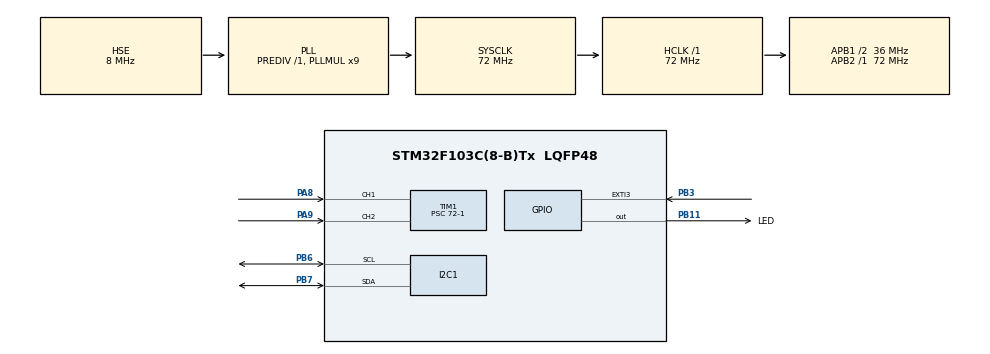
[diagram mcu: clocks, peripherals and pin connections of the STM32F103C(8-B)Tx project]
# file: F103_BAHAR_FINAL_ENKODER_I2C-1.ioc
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I2C1.I2C_Mode=I2C_Fast
Mcu.Family=STM32F1
Mcu.Name=STM32F103C(8-B)Tx
Mcu.Package=LQFP48
NVIC.EXTI3_IRQn=true\:0\:0\:false\:false\:true\:true\:true
NVIC.I2C1_ER_IRQn=true\:0\:0\:false\:false\:true\:true\:true
NVIC.I2C1_EV_IRQn=true\:0\:0\:false\:false\:true\:true\:true
NVIC.PriorityGroup=NVIC_PRIORITYGROUP_4
NVIC.TIM1_BRK_IRQn=true\:0\:0\:false\:false\:true\:true\:true
NVIC.TIM1_CC_IRQn=true\:0\:0\:false\:false\:true\:true\:true
NVIC.TIM1_TRG_COM_IRQn=true\:0\:0\:false\:false\:true\:true\:true
NVIC.TIM1_UP_IRQn=true\:0\:0\:false\:false\:true\:true\:true
PA13.Mode=Serial_Wire
PA13.Signal=SYS_JTMS-SWDIO
PA14.Mode=Serial_Wire
PA14.Signal=SYS_JTCK-SWCLK
PA8.Signal=S_TIM1_CH1
PA9.Signal=S_TIM1_CH2
PB11.GPIO_Label=LED
PB11.Signal=GPIO_Output
PB3.GPIO_ModeDefaultEXTI=GPIO_MODE_IT_RISING_FALLING
PB3.Signal=GPXTI3
PB6.Mode=I2C
PB6.Signal=I2C1_SCL
PB7.Mode=I2C
PB7.Signal=I2C1_SDA
PD0-OSC_IN.Mode=HSE-External-Oscillator
PD0-OSC_IN.Signal=RCC_OSC_IN
PD1-OSC_OUT.Mode=HSE-External-Oscillator
PD1-OSC_OUT.Signal=RCC_OSC_OUT
ProjectManager.HeapSize=0x200
ProjectManager.StackSize=0x400
ProjectManager.TargetToolchain=SW4STM32
RCC.AHBFreq_Value=72000000
RCC.APB1CLKDivider=RCC_HCLK_DIV2
RCC.APB1Freq_Value=36000000
RCC.APB1TimFreq_Value=72000000
RCC.APB2Freq_Value=72000000
RCC.APB2TimFreq_Value=72000000
RCC.HCLKFreq_Value=72000000
RCC.PLLMUL=RCC_PLL_MUL9
RCC.PLLSourceVirtual=RCC_PLLSOURCE_HSE
RCC.SYSCLKFreq_VALUE=72000000
RCC.SYSCLKSource=RCC_SYSCLKSOURCE_PLLCLK
RCC.USBFreq_Value=72000000
SH.S_TIM1_CH1.0=TIM1_CH1,Encoder_Interface
SH.S_TIM1_CH2.0=TIM1_CH2,Encoder_Interface
TIM1.EncoderMode=TIM_ENCODERMODE_TI12
TIM1.IC2Polarity=TIM_ICPOLARITY_FALLING
TIM1.Period=4096-1
TIM1.Prescaler=72-1
board=custom

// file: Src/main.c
/* USER CODE BEGIN Header */
/**
  ******************************************************************************
  * @file           : main.c
  * @brief          : Main program body
  ******************************************************************************
  * @attention
  *
  * <h2><center>&copy; Copyright (c) 2019 STMicroelectronics.
  * All rights reserved.</center></h2>
  *
  * This software component is licensed by ST under BSD 3-Clause license,
  * the "License"; You may not use this file except in compliance with the
  * License. You may obtain a copy of the License at:
  *                        opensource.org/licenses/BSD-3-Clause
  *
  ******************************************************************************
  */
/* USER CODE END Header */

#include "main.h"

I2C_HandleTypeDef hi2c1;

TIM_HandleTypeDef htim1;

void SystemClock_Config(void);
static void MX_GPIO_Init(void);
static void MX_TIM1_Init(void);
static void MX_I2C1_Init(void);

/* USER CODE BEGIN 0 */
uint8_t aRxBuffer;
uint8_t aTxBuffer[5];

uint8_t sistem_durumu=0;
uint8_t enkoder_durumu=0;
int encoder_value = 0;
char strBuffer[5];

/* USER CODE END 0 */

int main(void)
{

  /* MCU Configuration--------------------------------------------------------*/

  /* Reset of all peripherals, Initializes the Flash interface and the Systick. */
  HAL_Init();

  /* Configure the system clock */
  SystemClock_Config();

  /* Initialize all configured peripherals */
  MX_GPIO_Init();
  MX_TIM1_Init();
  MX_I2C1_Init();

  /* Infinite loop */
  /* USER CODE BEGIN WHILE */
  while (1)
  {
	  if(sistem_durumu==1 && enkoder_durumu==1)
	  {
		  encoder_value = __HAL_TIM_GET_COUNTER(&htim1);
	  }
	  else if (sistem_durumu==1 && enkoder_durumu==0){
		  sprintf(strBuffer, "%d\n", encoder_value);
		  while(HAL_I2C_Slave_Transmit(&hi2c1,  (uint8_t*)strBuffer, 5, 1000) != HAL_OK){
		  if (HAL_I2C_GetError(&hi2c1) != HAL_I2C_ERROR_AF)
		  {
			Error_Handler();
		  }
		  encoder_value=0;
	  }
 }

void HAL_I2C_SlaveRxCpltCallback(I2C_HandleTypeDef *hi2c)
{
	if(HAL_I2C_Slave_Receive(&hi2c1, (uint8_t *)aRxBuffer, 1, 1000)!= HAL_OK){
	    Error_Handler();
	  }
	  while (HAL_I2C_GetState(&hi2c1) != HAL_I2C_STATE_READY) {}
	 if(aRxBuffer==(uint8_t)"B"){
		 sistem_durumu=1;
		 HAL_GPIO_WritePin(GPIOB, GPIO_PIN_11, GPIO_PIN_SET);
	 }
	 if(aRxBuffer==(uint8_t)"D"){
		 sistem_durumu=0;
		 HAL_GPIO_WritePin(GPIOB, GPIO_PIN_11, GPIO_PIN_RESET);
	 }
}

void HAL_GPIO_EXTI_Callback(uint16_t GPIO_Pin)
{
  if(GPIO_Pin == GPIO_PIN_3)
  {
	  if(HAL_GPIO_ReadPin(GPIOB, GPIO_PIN_3)==1){
		  HAL_TIM_Encoder_Start(&htim1, TIM_CHANNEL_ALL);
		  enkoder_durumu = 1;
	  }
	  else{
		  HAL_TIM_Encoder_Stop(&htim1, TIM_CHANNEL_ALL);
		  enkoder_durumu = 0;
	  }
  }
}
void SystemClock_Config(void)
{
  RCC_OscInitTypeDef RCC_OscInitStruct = {0};
  RCC_ClkInitTypeDef RCC_ClkInitStruct = {0};

  /** Initializes the CPU, AHB and APB busses clocks
  */
  RCC_OscInitStruct.OscillatorType = RCC_OSCILLATORTYPE_HSE;
  RCC_OscInitStruct.HSEState = RCC_HSE_ON;
  RCC_OscInitStruct.HSEPredivValue = RCC_HSE_PREDIV_DIV1;
  RCC_OscInitStruct.HSIState = RCC_HSI_ON;
  RCC_OscInitStruct.PLL.PLLState = RCC_PLL_ON;
  RCC_OscInitStruct.PLL.PLLSource = RCC_PLLSOURCE_HSE;
  RCC_OscInitStruct.PLL.PLLMUL = RCC_PLL_MUL9;
  if (HAL_RCC_OscConfig(&RCC_OscInitStruct) != HAL_OK)
  {
    Error_Handler();
  }
  /** Initializes the CPU, AHB and APB busses clocks
  */
  RCC_ClkInitStruct.ClockType = RCC_CLOCKTYPE_HCLK|RCC_CLOCKTYPE_SYSCLK
                              |RCC_CLOCKTYPE_PCLK1|RCC_CLOCKTYPE_PCLK2;
  RCC_ClkInitStruct.SYSCLKSource = RCC_SYSCLKSOURCE_PLLCLK;
  RCC_ClkInitStruct.AHBCLKDivider = RCC_SYSCLK_DIV1;
  RCC_ClkInitStruct.APB1CLKDivider = RCC_HCLK_DIV2;
  RCC_ClkInitStruct.APB2CLKDivider = RCC_HCLK_DIV1;

  if (HAL_RCC_ClockConfig(&RCC_ClkInitStruct, FLASH_LATENCY_2) != HAL_OK)
  {
    Error_Handler();
  }
}

static void MX_I2C1_Init(void)
{

  hi2c1.Instance = I2C1;
  hi2c1.Init.ClockSpeed = 400000;
  hi2c1.Init.DutyCycle = I2C_DUTYCYCLE_2;
  hi2c1.Init.OwnAddress1 = 0;
  hi2c1.Init.AddressingMode = I2C_ADDRESSINGMODE_7BIT;
  hi2c1.Init.DualAddressMode = I2C_DUALADDRESS_DISABLE;
  hi2c1.Init.OwnAddress2 = 0;
  hi2c1.Init.GeneralCallMode = I2C_GENERALCALL_DISABLE;
  hi2c1.Init.NoStretchMode = I2C_NOSTRETCH_DISABLE;
  if (HAL_I2C_Init(&hi2c1) != HAL_OK)
  {
    Error_Handler();
  }

}

static void MX_TIM1_Init(void)
{

  TIM_Encoder_InitTypeDef sConfig = {0};
  TIM_MasterConfigTypeDef sMasterConfig = {0};

  htim1.Instance = TIM1;
  htim1.Init.Prescaler = 72-1;
  htim1.Init.CounterMode = TIM_COUNTERMODE_UP;
  htim1.Init.Period = 4096-1;
  htim1.Init.ClockDivision = TIM_CLOCKDIVISION_DIV1;
  htim1.Init.RepetitionCounter = 0;
  htim1.Init.AutoReloadPreload = TIM_AUTORELOAD_PRELOAD_DISABLE;
  sConfig.EncoderMode = TIM_ENCODERMODE_TI12;
  sConfig.IC1Polarity = TIM_ICPOLARITY_RISING;
  sConfig.IC1Selection = TIM_ICSELECTION_DIRECTTI;
  sConfig.IC1Prescaler = TIM_ICPSC_DIV1;
  sConfig.IC1Filter = 0;
  sConfig.IC2Polarity = TIM_ICPOLARITY_FALLING;
  sConfig.IC2Selection = TIM_ICSELECTION_DIRECTTI;
  sConfig.IC2Prescaler = TIM_ICPSC_DIV1;
  sConfig.IC2Filter = 0;
  if (HAL_TIM_Encoder_Init(&htim1, &sConfig) != HAL_OK)
  {
    Error_Handler();
  }
  sMasterConfig.MasterOutputTrigger = TIM_TRGO_RESET;
  sMasterConfig.MasterSlaveMode = TIM_MASTERSLAVEMODE_DISABLE;
  if (HAL_TIMEx_MasterConfigSynchronization(&htim1, &sMasterConfig) != HAL_OK)
  {
    Error_Handler();
  }

}

static void MX_GPIO_Init(void)
{
  GPIO_InitTypeDef GPIO_InitStruct = {0};

  /* GPIO Ports Clock Enable */
  __HAL_RCC_GPIOD_CLK_ENABLE();
  __HAL_RCC_GPIOB_CLK_ENABLE();
  __HAL_RCC_GPIOA_CLK_ENABLE();

  /*Configure GPIO pin Output Level */
  HAL_GPIO_WritePin(LED_GPIO_Port, LED_Pin, GPIO_PIN_RESET);

  /*Configure GPIO pin : LED_Pin */
  GPIO_InitStruct.Pin = LED_Pin;
  GPIO_InitStruct.Mode = GPIO_MODE_OUTPUT_PP;
  GPIO_InitStruct.Pull = GPIO_NOPULL;
  GPIO_InitStruct.Speed = GPIO_SPEED_FREQ_LOW;
  HAL_GPIO_Init(LED_GPIO_Port, &GPIO_InitStruct);

  /*Configure GPIO pin : PB3 */
  GPIO_InitStruct.Pin = GPIO_PIN_3;
  GPIO_InitStruct.Mode = GPIO_MODE_IT_RISING_FALLING;
  GPIO_InitStruct.Pull = GPIO_NOPULL;
  HAL_GPIO_Init(GPIOB, &GPIO_InitStruct);

  /* EXTI interrupt init*/
  HAL_NVIC_SetPriority(EXTI3_IRQn, 0, 0);
  HAL_NVIC_EnableIRQ(EXTI3_IRQn);

}

void Error_Handler(void)
{
}

/************************ (C) COPYRIGHT STMicroelectronics *****END OF FILE****/
